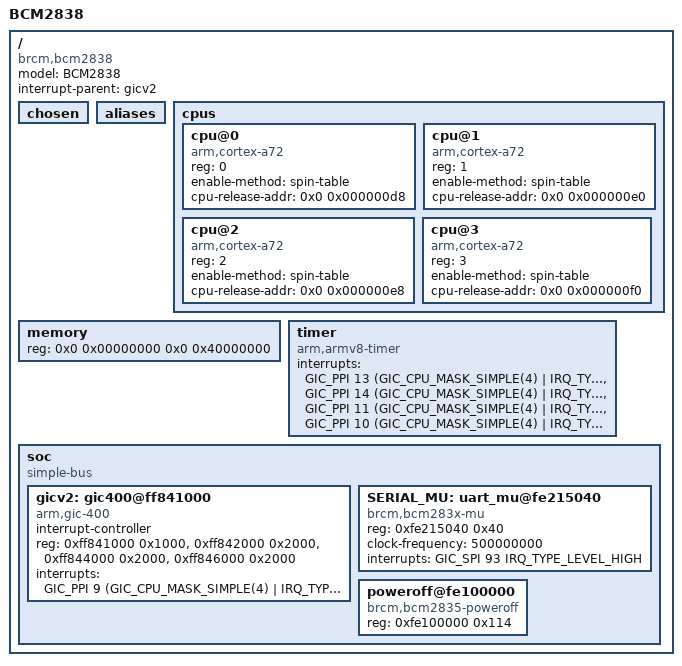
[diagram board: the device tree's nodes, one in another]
#include <dt-bindings/interrupt-controller/arm-gic.h>

/memreserve/ 0x00000000 0x00008000;

/ {
	#address-cells = <2>;
	#size-cells = <2>;
	compatible = "brcm,bcm2838";
	model = "BCM2838";
	interrupt-parent = <&gicv2>;

	chosen { };
	aliases { };

	cpus {
		#address-cells = <1>;
		#size-cells = <0>;

		cpu@0 {
			device_type = "cpu";
			compatible = "arm,cortex-a72";
			reg = <0>;
			enable-method = "spin-table";
			cpu-release-addr = <0x0 0x000000d8>;
		};

		cpu@1 {
			device_type = "cpu";
			compatible = "arm,cortex-a72";
			reg = <1>;
			enable-method = "spin-table";
			cpu-release-addr = <0x0 0x000000e0>;
		};

		cpu@2 {
			device_type = "cpu";
			compatible = "arm,cortex-a72";
			reg = <2>;
			enable-method = "spin-table";
			cpu-release-addr = <0x0 0x000000e8>;
		};

		cpu@3 {
			device_type = "cpu";
			compatible = "arm,cortex-a72";
			reg = <3>;
			enable-method = "spin-table";
			cpu-release-addr = <0x0 0x000000f0>;
		};
	};

	memory {
		device_type = "memory";
		reg = <0x0 0x00000000 0x0 0x40000000>; /* 1 GB */
	};

	timer { /* Generic Timer */
		compatible = "arm,armv8-timer";
		interrupts = <GIC_PPI 13 (GIC_CPU_MASK_SIMPLE(4) |
					  IRQ_TYPE_LEVEL_LOW)>,
			     <GIC_PPI 14 (GIC_CPU_MASK_SIMPLE(4) |
					  IRQ_TYPE_LEVEL_LOW)>,
			     <GIC_PPI 11 (GIC_CPU_MASK_SIMPLE(4) |
					  IRQ_TYPE_LEVEL_LOW)>,
			     <GIC_PPI 10 (GIC_CPU_MASK_SIMPLE(4) |
					  IRQ_TYPE_LEVEL_LOW)>;
	};

	soc: soc {
		#address-cells = <1>;
		#size-cells = <1>;
		compatible = "simple-bus";

		gicv2: gic400@ff841000 {
			interrupt-controller;
			#interrupt-cells = <3>;
			compatible = "arm,gic-400";
			reg = <0xff841000 0x1000>,
			      <0xff842000 0x2000>,
			      <0xff844000 0x2000>,
			      <0xff846000 0x2000>;
			interrupts = <GIC_PPI 9 (GIC_CPU_MASK_SIMPLE(4) |
						 IRQ_TYPE_LEVEL_HIGH)>;
		};

		SERIAL_MU: uart_mu@fe215040 {
			compatible = "brcm,bcm283x-mu";
			reg = <0xfe215040 0x40>;
			status = "okay";
			clock-frequency = <500000000>;
			interrupts = <GIC_SPI 93 IRQ_TYPE_LEVEL_HIGH>;
		};

		poweroff@fe100000 {
			compatible = "brcm,bcm2835-poweroff";
			reg = <0xfe100000 0x114>;
		};
	};
};
